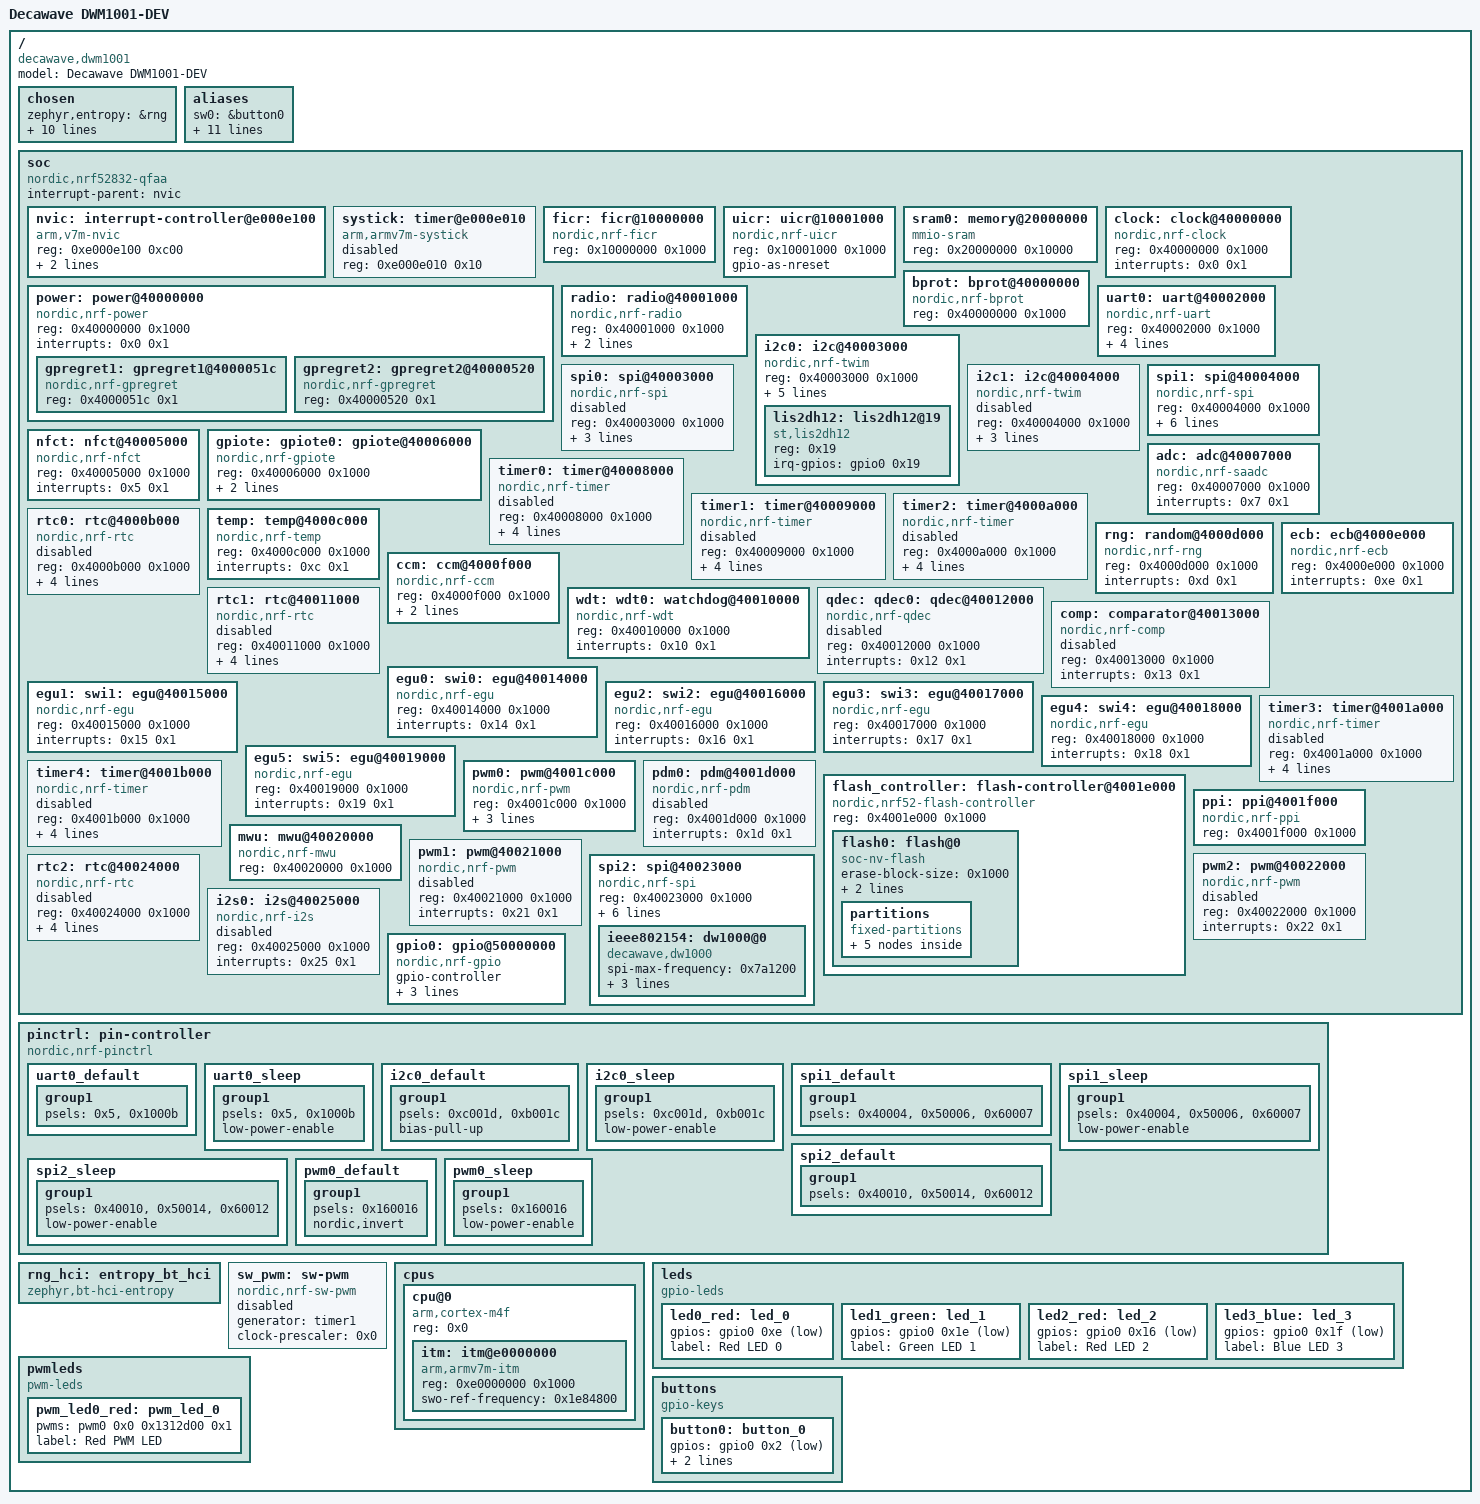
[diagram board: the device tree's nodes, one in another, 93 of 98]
/dts-v1/;

/ {
	#address-cells = < 0x1 >;
	#size-cells = < 0x1 >;
	model = "Decawave DWM1001-DEV";
	compatible = "decawave,dwm1001";
	chosen {
		zephyr,entropy = &rng;
		zephyr,flash-controller = &flash_controller;
		zephyr,console = &uart0;
		zephyr,shell-uart = &uart0;
		zephyr,uart-mcumgr = &uart0;
		zephyr,bt-mon-uart = &uart0;
		zephyr,bt-c2h-uart = &uart0;
		zephyr,sram = &sram0;
		zephyr,flash = &flash0;
		zephyr,code-partition = &slot0_partition;
		zephyr,ieee802154 = &ieee802154;
	};
	aliases {
		sw0 = &button0;
		led0 = &led0_red;
		led1 = &led1_green;
		led2 = &led2_red;
		led3 = &led3_blue;
		led0-red = &led0_red;
		led1-green = &led1_green;
		led2-red = &led2_red;
		led3-blue = &led3_blue;
		pwm-led0 = &pwm_led0_red;
		watchdog0 = &wdt0;
		accel0 = &lis2dh12;
	};
	soc {
		#address-cells = < 0x1 >;
		#size-cells = < 0x1 >;
		compatible = "nordic,nrf52832-qfaa", "nordic,nrf52832", "nordic,nrf52", "simple-bus";
		interrupt-parent = < &nvic >;
		ranges;
		nvic: interrupt-controller@e000e100 {
			#address-cells = < 0x1 >;
			compatible = "arm,v7m-nvic";
			reg = < 0xe000e100 0xc00 >;
			interrupt-controller;
			#interrupt-cells = < 0x2 >;
			arm,num-irq-priority-bits = < 0x3 >;
			phandle = < 0x1 >;
		};
		systick: timer@e000e010 {
			compatible = "arm,armv7m-systick";
			reg = < 0xe000e010 0x10 >;
			status = "disabled";
		};
		ficr: ficr@10000000 {
			compatible = "nordic,nrf-ficr";
			reg = < 0x10000000 0x1000 >;
			#nordic,ficr-cells = < 0x1 >;
			status = "okay";
		};
		uicr: uicr@10001000 {
			compatible = "nordic,nrf-uicr";
			reg = < 0x10001000 0x1000 >;
			status = "okay";
			gpio-as-nreset;
		};
		sram0: memory@20000000 {
			compatible = "mmio-sram";
			reg = < 0x20000000 0x10000 >;
		};
		clock: clock@40000000 {
			compatible = "nordic,nrf-clock";
			reg = < 0x40000000 0x1000 >;
			interrupts = < 0x0 0x1 >;
			status = "okay";
		};
		power: power@40000000 {
			compatible = "nordic,nrf-power";
			reg = < 0x40000000 0x1000 >;
			interrupts = < 0x0 0x1 >;
			status = "okay";
			#address-cells = < 0x1 >;
			#size-cells = < 0x1 >;
			gpregret1: gpregret1@4000051c {
				#address-cells = < 0x1 >;
				#size-cells = < 0x1 >;
				compatible = "nordic,nrf-gpregret";
				reg = < 0x4000051c 0x1 >;
				status = "okay";
			};
			gpregret2: gpregret2@40000520 {
				#address-cells = < 0x1 >;
				#size-cells = < 0x1 >;
				compatible = "nordic,nrf-gpregret";
				reg = < 0x40000520 0x1 >;
				status = "okay";
			};
		};
		bprot: bprot@40000000 {
			compatible = "nordic,nrf-bprot";
			reg = < 0x40000000 0x1000 >;
			status = "okay";
		};
		radio: radio@40001000 {
			compatible = "nordic,nrf-radio";
			reg = < 0x40001000 0x1000 >;
			interrupts = < 0x1 0x1 >;
			status = "okay";
			ble-2mbps-supported;
		};
		uart0: uart@40002000 {
			compatible = "nordic,nrf-uart";
			reg = < 0x40002000 0x1000 >;
			interrupts = < 0x2 0x1 >;
			status = "okay";
			current-speed = < 0x1c200 >;
			pinctrl-0 = < &uart0_default >;
			pinctrl-1 = < &uart0_sleep >;
			pinctrl-names = "default", "sleep";
		};
		i2c0: i2c@40003000 {
			compatible = "nordic,nrf-twim";
			#address-cells = < 0x1 >;
			#size-cells = < 0x0 >;
			reg = < 0x40003000 0x1000 >;
			clock-frequency = < 0x61a80 >;
			interrupts = < 0x3 0x1 >;
			easydma-maxcnt-bits = < 0x8 >;
			status = "okay";
			pinctrl-0 = < &i2c0_default >;
			pinctrl-1 = < &i2c0_sleep >;
			pinctrl-names = "default", "sleep";
			lis2dh12: lis2dh12@19 {
				compatible = "st,lis2dh12", "st,lis2dh";
				reg = < 0x19 >;
				irq-gpios = < &gpio0 0x19 0x0 >;
			};
		};
		spi0: spi@40003000 {
			compatible = "nordic,nrf-spi";
			#address-cells = < 0x1 >;
			#size-cells = < 0x0 >;
			reg = < 0x40003000 0x1000 >;
			interrupts = < 0x3 0x1 >;
			max-frequency = < 0x7a1200 >;
			easydma-maxcnt-bits = < 0x8 >;
			status = "disabled";
		};
		i2c1: i2c@40004000 {
			compatible = "nordic,nrf-twim";
			#address-cells = < 0x1 >;
			#size-cells = < 0x0 >;
			reg = < 0x40004000 0x1000 >;
			clock-frequency = < 0x186a0 >;
			interrupts = < 0x4 0x1 >;
			easydma-maxcnt-bits = < 0x8 >;
			status = "disabled";
		};
		spi1: spi@40004000 {
			compatible = "nordic,nrf-spi";
			#address-cells = < 0x1 >;
			#size-cells = < 0x0 >;
			reg = < 0x40004000 0x1000 >;
			interrupts = < 0x4 0x1 >;
			max-frequency = < 0x7a1200 >;
			easydma-maxcnt-bits = < 0x8 >;
			status = "okay";
			cs-gpios = < &gpio0 0x3 0x0 >;
			pinctrl-0 = < &spi1_default >;
			pinctrl-1 = < &spi1_sleep >;
			pinctrl-names = "default", "sleep";
		};
		nfct: nfct@40005000 {
			compatible = "nordic,nrf-nfct";
			reg = < 0x40005000 0x1000 >;
			interrupts = < 0x5 0x1 >;
			status = "okay";
		};
		gpiote: gpiote0: gpiote@40006000 {
			compatible = "nordic,nrf-gpiote";
			reg = < 0x40006000 0x1000 >;
			interrupts = < 0x6 0x5 >;
			status = "okay";
			instance = < 0x0 >;
			phandle = < 0xd >;
		};
		adc: adc@40007000 {
			compatible = "nordic,nrf-saadc";
			reg = < 0x40007000 0x1000 >;
			interrupts = < 0x7 0x1 >;
			status = "okay";
			#io-channel-cells = < 0x1 >;
		};
		timer0: timer@40008000 {
			compatible = "nordic,nrf-timer";
			status = "disabled";
			reg = < 0x40008000 0x1000 >;
			cc-num = < 0x4 >;
			max-bit-width = < 0x20 >;
			interrupts = < 0x8 0x1 >;
			prescaler = < 0x0 >;
		};
		timer1: timer@40009000 {
			compatible = "nordic,nrf-timer";
			status = "disabled";
			reg = < 0x40009000 0x1000 >;
			cc-num = < 0x4 >;
			max-bit-width = < 0x20 >;
			interrupts = < 0x9 0x1 >;
			prescaler = < 0x0 >;
			phandle = < 0xe >;
		};
		timer2: timer@4000a000 {
			compatible = "nordic,nrf-timer";
			status = "disabled";
			reg = < 0x4000a000 0x1000 >;
			cc-num = < 0x4 >;
			max-bit-width = < 0x20 >;
			interrupts = < 0xa 0x1 >;
			prescaler = < 0x0 >;
		};
		rtc0: rtc@4000b000 {
			compatible = "nordic,nrf-rtc";
			reg = < 0x4000b000 0x1000 >;
			cc-num = < 0x3 >;
			interrupts = < 0xb 0x1 >;
			status = "disabled";
			clock-frequency = < 0x8000 >;
			prescaler = < 0x1 >;
		};
		temp: temp@4000c000 {
			compatible = "nordic,nrf-temp";
			reg = < 0x4000c000 0x1000 >;
			interrupts = < 0xc 0x1 >;
			status = "okay";
		};
		rng: random@4000d000 {
			compatible = "nordic,nrf-rng";
			reg = < 0x4000d000 0x1000 >;
			interrupts = < 0xd 0x1 >;
			status = "okay";
		};
		ecb: ecb@4000e000 {
			compatible = "nordic,nrf-ecb";
			reg = < 0x4000e000 0x1000 >;
			interrupts = < 0xe 0x1 >;
			status = "okay";
		};
		ccm: ccm@4000f000 {
			compatible = "nordic,nrf-ccm";
			reg = < 0x4000f000 0x1000 >;
			interrupts = < 0xf 0x1 >;
			length-field-length-8-bits;
			status = "okay";
		};
		wdt: wdt0: watchdog@40010000 {
			compatible = "nordic,nrf-wdt";
			reg = < 0x40010000 0x1000 >;
			interrupts = < 0x10 0x1 >;
			status = "okay";
		};
		rtc1: rtc@40011000 {
			compatible = "nordic,nrf-rtc";
			reg = < 0x40011000 0x1000 >;
			cc-num = < 0x4 >;
			interrupts = < 0x11 0x1 >;
			status = "disabled";
			clock-frequency = < 0x8000 >;
			prescaler = < 0x1 >;
		};
		qdec: qdec0: qdec@40012000 {
			compatible = "nordic,nrf-qdec";
			reg = < 0x40012000 0x1000 >;
			interrupts = < 0x12 0x1 >;
			status = "disabled";
		};
		comp: comparator@40013000 {
			compatible = "nordic,nrf-comp";
			reg = < 0x40013000 0x1000 >;
			interrupts = < 0x13 0x1 >;
			status = "disabled";
			#io-channel-cells = < 0x1 >;
		};
		egu0: swi0: egu@40014000 {
			compatible = "nordic,nrf-egu", "nordic,nrf-swi";
			reg = < 0x40014000 0x1000 >;
			interrupts = < 0x14 0x1 >;
			status = "okay";
		};
		egu1: swi1: egu@40015000 {
			compatible = "nordic,nrf-egu", "nordic,nrf-swi";
			reg = < 0x40015000 0x1000 >;
			interrupts = < 0x15 0x1 >;
			status = "okay";
		};
		egu2: swi2: egu@40016000 {
			compatible = "nordic,nrf-egu", "nordic,nrf-swi";
			reg = < 0x40016000 0x1000 >;
			interrupts = < 0x16 0x1 >;
			status = "okay";
		};
		egu3: swi3: egu@40017000 {
			compatible = "nordic,nrf-egu", "nordic,nrf-swi";
			reg = < 0x40017000 0x1000 >;
			interrupts = < 0x17 0x1 >;
			status = "okay";
		};
		egu4: swi4: egu@40018000 {
			compatible = "nordic,nrf-egu", "nordic,nrf-swi";
			reg = < 0x40018000 0x1000 >;
			interrupts = < 0x18 0x1 >;
			status = "okay";
		};
		egu5: swi5: egu@40019000 {
			compatible = "nordic,nrf-egu", "nordic,nrf-swi";
			reg = < 0x40019000 0x1000 >;
			interrupts = < 0x19 0x1 >;
			status = "okay";
		};
		timer3: timer@4001a000 {
			compatible = "nordic,nrf-timer";
			status = "disabled";
			reg = < 0x4001a000 0x1000 >;
			cc-num = < 0x6 >;
			max-bit-width = < 0x20 >;
			interrupts = < 0x1a 0x1 >;
			prescaler = < 0x0 >;
		};
		timer4: timer@4001b000 {
			compatible = "nordic,nrf-timer";
			status = "disabled";
			reg = < 0x4001b000 0x1000 >;
			cc-num = < 0x6 >;
			max-bit-width = < 0x20 >;
			interrupts = < 0x1b 0x1 >;
			prescaler = < 0x0 >;
		};
		pwm0: pwm@4001c000 {
			compatible = "nordic,nrf-pwm";
			reg = < 0x4001c000 0x1000 >;
			interrupts = < 0x1c 0x1 >;
			status = "okay";
			#pwm-cells = < 0x3 >;
			pinctrl-0 = < &pwm0_default >;
			pinctrl-1 = < &pwm0_sleep >;
			pinctrl-names = "default", "sleep";
			phandle = < 0xf >;
		};
		pdm0: pdm@4001d000 {
			compatible = "nordic,nrf-pdm";
			reg = < 0x4001d000 0x1000 >;
			interrupts = < 0x1d 0x1 >;
			status = "disabled";
		};
		flash_controller: flash-controller@4001e000 {
			compatible = "nordic,nrf52-flash-controller";
			reg = < 0x4001e000 0x1000 >;
			#address-cells = < 0x1 >;
			#size-cells = < 0x1 >;
			flash0: flash@0 {
				compatible = "soc-nv-flash";
				erase-block-size = < 0x1000 >;
				write-block-size = < 0x4 >;
				reg = < 0x0 0x80000 >;
				partitions {
					compatible = "fixed-partitions";
					#address-cells = < 0x1 >;
					#size-cells = < 0x1 >;
					boot_partition: partition@0 {
						label = "mcuboot";
						reg = < 0x0 0xc000 >;
					};
					slot0_partition: partition@c000 {
						label = "image-0";
						reg = < 0xc000 0x32000 >;
					};
					slot1_partition: partition@3e000 {
						label = "image-1";
						reg = < 0x3e000 0x32000 >;
					};
					scratch_partition: partition@70000 {
						label = "image-scratch";
						reg = < 0x70000 0xa000 >;
					};
					storage_partition: partition@7a000 {
						label = "storage";
						reg = < 0x7a000 0x6000 >;
					};
				};
			};
		};
		ppi: ppi@4001f000 {
			compatible = "nordic,nrf-ppi";
			reg = < 0x4001f000 0x1000 >;
			status = "okay";
		};
		mwu: mwu@40020000 {
			compatible = "nordic,nrf-mwu";
			reg = < 0x40020000 0x1000 >;
			status = "okay";
		};
		pwm1: pwm@40021000 {
			compatible = "nordic,nrf-pwm";
			reg = < 0x40021000 0x1000 >;
			interrupts = < 0x21 0x1 >;
			status = "disabled";
			#pwm-cells = < 0x3 >;
		};
		pwm2: pwm@40022000 {
			compatible = "nordic,nrf-pwm";
			reg = < 0x40022000 0x1000 >;
			interrupts = < 0x22 0x1 >;
			status = "disabled";
			#pwm-cells = < 0x3 >;
		};
		spi2: spi@40023000 {
			compatible = "nordic,nrf-spi";
			#address-cells = < 0x1 >;
			#size-cells = < 0x0 >;
			reg = < 0x40023000 0x1000 >;
			interrupts = < 0x23 0x1 >;
			max-frequency = < 0x7a1200 >;
			easydma-maxcnt-bits = < 0x8 >;
			status = "okay";
			cs-gpios = < &gpio0 0x11 0x1 >;
			pinctrl-0 = < &spi2_default >;
			pinctrl-1 = < &spi2_sleep >;
			pinctrl-names = "default", "sleep";
			ieee802154: dw1000@0 {
				compatible = "decawave,dw1000";
				spi-max-frequency = < 0x7a1200 >;
				int-gpios = < &gpio0 0x13 0x0 >;
				reset-gpios = < &gpio0 0x18 0x1 >;
				status = "okay";
				reg = < 0x0 >;
			};
		};
		rtc2: rtc@40024000 {
			compatible = "nordic,nrf-rtc";
			reg = < 0x40024000 0x1000 >;
			cc-num = < 0x4 >;
			interrupts = < 0x24 0x1 >;
			status = "disabled";
			clock-frequency = < 0x8000 >;
			prescaler = < 0x1 >;
		};
		i2s0: i2s@40025000 {
			compatible = "nordic,nrf-i2s";
			#address-cells = < 0x1 >;
			#size-cells = < 0x0 >;
			reg = < 0x40025000 0x1000 >;
			interrupts = < 0x25 0x1 >;
			status = "disabled";
		};
		gpio0: gpio@50000000 {
			compatible = "nordic,nrf-gpio";
			gpio-controller;
			reg = < 0x50000000 0x1000 >;
			#gpio-cells = < 0x2 >;
			status = "okay";
			port = < 0x0 >;
			gpiote-instance = < &gpiote >;
			phandle = < 0x6 >;
		};
	};
	pinctrl: pin-controller {
		compatible = "nordic,nrf-pinctrl";
		uart0_default: uart0_default {
			phandle = < 0x2 >;
			group1 {
				psels = < 0x5 >, < 0x1000b >;
			};
		};
		uart0_sleep: uart0_sleep {
			phandle = < 0x3 >;
			group1 {
				psels = < 0x5 >, < 0x1000b >;
				low-power-enable;
			};
		};
		i2c0_default: i2c0_default {
			phandle = < 0x4 >;
			group1 {
				psels = < 0xc001d >, < 0xb001c >;
				bias-pull-up;
			};
		};
		i2c0_sleep: i2c0_sleep {
			phandle = < 0x5 >;
			group1 {
				psels = < 0xc001d >, < 0xb001c >;
				low-power-enable;
			};
		};
		spi1_default: spi1_default {
			phandle = < 0x7 >;
			group1 {
				psels = < 0x40004 >, < 0x50006 >, < 0x60007 >;
			};
		};
		spi1_sleep: spi1_sleep {
			phandle = < 0x8 >;
			group1 {
				psels = < 0x40004 >, < 0x50006 >, < 0x60007 >;
				low-power-enable;
			};
		};
		spi2_default: spi2_default {
			phandle = < 0xb >;
			group1 {
				psels = < 0x40010 >, < 0x50014 >, < 0x60012 >;
			};
		};
		spi2_sleep: spi2_sleep {
			phandle = < 0xc >;
			group1 {
				psels = < 0x40010 >, < 0x50014 >, < 0x60012 >;
				low-power-enable;
			};
		};
		pwm0_default: pwm0_default {
			phandle = < 0x9 >;
			group1 {
				psels = < 0x160016 >;
				nordic,invert;
			};
		};
		pwm0_sleep: pwm0_sleep {
			phandle = < 0xa >;
			group1 {
				psels = < 0x160016 >;
				low-power-enable;
			};
		};
	};
	rng_hci: entropy_bt_hci {
		compatible = "zephyr,bt-hci-entropy";
		status = "okay";
	};
	sw_pwm: sw-pwm {
		compatible = "nordic,nrf-sw-pwm";
		status = "disabled";
		generator = < &timer1 >;
		clock-prescaler = < 0x0 >;
		#pwm-cells = < 0x3 >;
	};
	cpus {
		#address-cells = < 0x1 >;
		#size-cells = < 0x0 >;
		cpu@0 {
			device_type = "cpu";
			compatible = "arm,cortex-m4f";
			reg = < 0x0 >;
			#address-cells = < 0x1 >;
			#size-cells = < 0x1 >;
			itm: itm@e0000000 {
				compatible = "arm,armv7m-itm";
				reg = < 0xe0000000 0x1000 >;
				swo-ref-frequency = < 0x1e84800 >;
			};
		};
	};
	leds {
		compatible = "gpio-leds";
		led0_red: led_0 {
			gpios = < &gpio0 0xe 0x1 >;
			label = "Red LED 0";
		};
		led1_green: led_1 {
			gpios = < &gpio0 0x1e 0x1 >;
			label = "Green LED 1";
		};
		led2_red: led_2 {
			gpios = < &gpio0 0x16 0x1 >;
			label = "Red LED 2";
		};
		led3_blue: led_3 {
			gpios = < &gpio0 0x1f 0x1 >;
			label = "Blue LED 3";
		};
	};
	pwmleds {
		compatible = "pwm-leds";
		pwm_led0_red: pwm_led_0 {
			pwms = < &pwm0 0x0 0x1312d00 0x1 >;
			label = "Red PWM LED";
		};
	};
	buttons {
		compatible = "gpio-keys";
		button0: button_0 {
			gpios = < &gpio0 0x2 0x11 >;
			label = "Push button switch 0";
			zephyr,code = < 0xb >;
		};
	};
};
